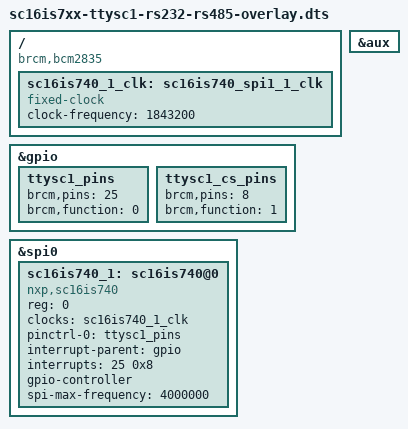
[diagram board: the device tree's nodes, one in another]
/dts-v1/;
/plugin/;

/ {
	compatible = "brcm,bcm2835", "brcm,bcm2708", "brcm,bcm2709";

	fragment@0 {
		target = <&gpio>;
		__overlay__ {

			ttysc1_pins: ttysc1_pins {
				brcm,pins = <25>;
				brcm,function = <0>; /* input */
			};
      
			ttysc1_cs_pins: ttysc1_cs_pins {
				brcm,pins = <8>;
				brcm,function = <1>; /* output */
			};
		};
	};

	fragment@1 {
		target = <&spi0>;
		__overlay__ {
			#address-cells = <1>;
			#size-cells = <0>;
			pinctrl-names = "default";
			status = "okay";

			sc16is740_1: sc16is740@0 {
				compatible = "nxp,sc16is740";
				reg = <0>; /* CE0 */
				clocks = <&sc16is740_1_clk>;
				pinctrl-0 = <&ttysc1_pins>;
				interrupt-parent = <&gpio>;
				interrupts = <25 0x8>; /* IRQ_TYPE_LEVEL_LOW */				
				gpio-controller;
				#gpio-cells = <2>;
				spi-max-frequency = <4000000>;
			};
		};
	};

	fragment@2 {
		target = <&aux>;
		__overlay__ {
			status = "okay";
		};
	};

	fragment@3 {
		target-path = "/";
		__overlay__ {
			sc16is740_1_clk: sc16is740_spi1_1_clk {
				compatible = "fixed-clock";
				#clock-cells = <0>;
				clock-frequency = <1843200>;
			};
		};
	};

    __overrides__ {
      int_pin = <&sc16is740_1>,"interrupts:0";
    };
};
